# STM32F407 register map
File version: 1.4
CPU: CM4 r0p1, little endian, MPU, FPU, 4 interrupt priority bits
Registers are 32-bit, read-write, reset 0x0 unless marked. A register's access mark holds for its fields unless they carry their own. Offsets are from the block's base; [hi:lo] are bit positions; {n}, {i} and the like mark numbered series.

## GPIOA — General-purpose I/Os
Base 0x40020000
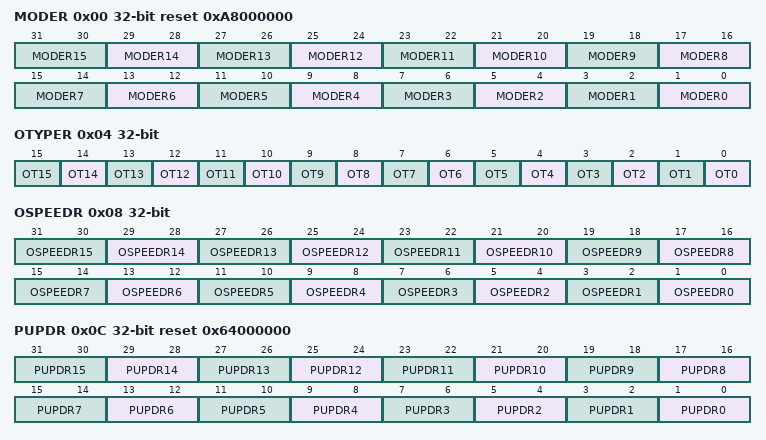
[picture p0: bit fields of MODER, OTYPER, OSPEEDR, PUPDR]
0x00 MODER reset 0xA8000000 — GPIO port mode register
  [2n+1:2n] MODER{n} (n=0..15) — Port x configuration bits (y = 0..15)
0x04 OTYPER — GPIO port output type register
  [n] OT{n} (n=0..15) — Port x configuration bits (y = 0..15)
0x08 OSPEEDR — GPIO port output speed register
  [2n+1:2n] OSPEEDR{n} (n=0..15) — Port x configuration bits (y = 0..15)
0x0C PUPDR reset 0x64000000 — GPIO port pull-up/pull-down register
  [2n+1:2n] PUPDR{n} (n=0..15) — Port x configuration bits (y = 0..15)
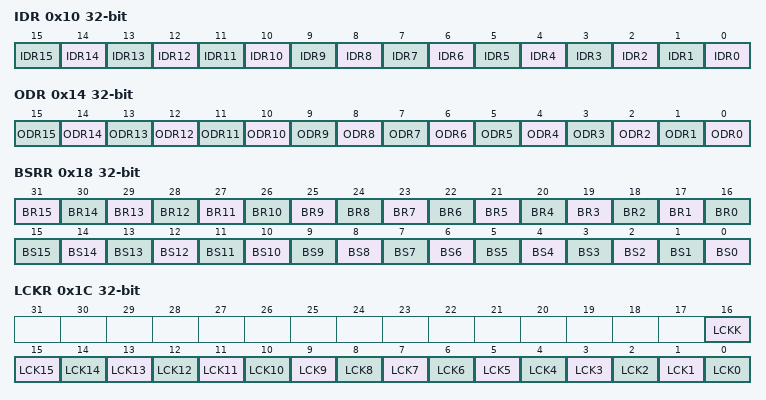
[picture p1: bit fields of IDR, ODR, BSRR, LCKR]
0x10 IDR ro — GPIO port input data register
  [n] IDR{n} (n=0..15) — Port input data (y = 0..15)
0x14 ODR — GPIO port output data register
  [n] ODR{n} (n=0..15) — Port output data (y = 0..15)
0x18 BSRR wo — GPIO port bit set/reset register
  [n+16] BR{n} (n=1..15) — Port x reset bit y (y = 0..15)
  [16] BR0 — Port x set bit y (y= 0..15)
  [n] BS{n} (n=0..15) — Port x set bit y (y= 0..15)
0x1C LCKR — GPIO port configuration lock register
  [16] LCKK — Port x lock bit y (y= 0..15)
  [n] LCK{n} (n=0..15) — Port x lock bit y (y= 0..15)
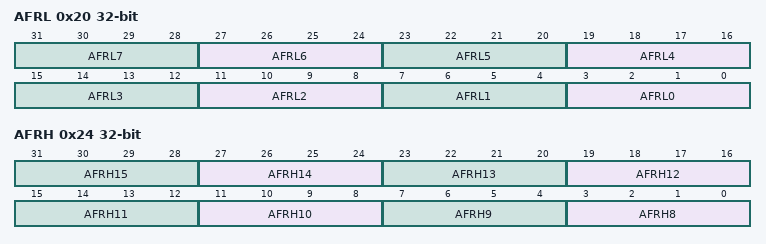
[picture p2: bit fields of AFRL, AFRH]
0x20 AFRL — GPIO alternate function low register
  [4n+3:4n] AFRL{n} (n=0..7) — Alternate function selection for port x bit y (y = 0..7)
0x24 AFRH — GPIO alternate function high register
  [4n-29:4n-32] AFRH{n} (n=8..15) — Alternate function selection for port x bit y (y = 8..15)

## GPIOB — General-purpose I/Os
Base 0x40020400
Registers as GPIOA; these are added or differ:
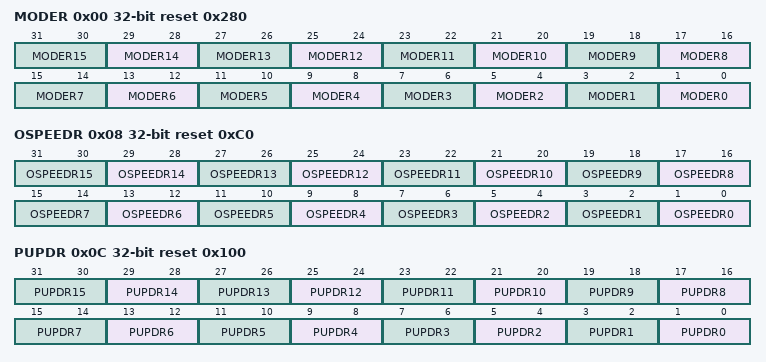
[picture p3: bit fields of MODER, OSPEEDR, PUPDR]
0x00 MODER reset 0x280 — GPIO port mode register
  [2n+1:2n] MODER{n} (n=0..15) — Port x configuration bits (y = 0..15)
0x08 OSPEEDR reset 0xC0 — GPIO port output speed register
  [2n+1:2n] OSPEEDR{n} (n=0..15) — Port x configuration bits (y = 0..15)
0x0C PUPDR reset 0x100 — GPIO port pull-up/pull-down register
  [2n+1:2n] PUPDR{n} (n=0..15) — Port x configuration bits (y = 0..15)

## GPIOC — General-purpose I/Os
Base 0x40020800
Same registers: GPIOD 0x40020C00, GPIOE 0x40021000, GPIOF 0x40021400, GPIOG 0x40021800, GPIOH 0x40021C00, GPIOI 0x40022000, GPIOJ 0x40022400, GPIOK 0x40022800
Registers as GPIOA; these are added or differ:
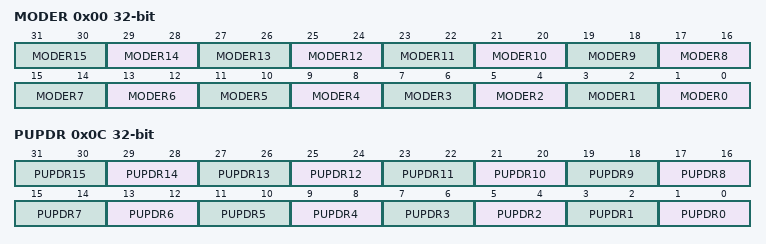
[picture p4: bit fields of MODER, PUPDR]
0x00 MODER — GPIO port mode register
  [2n+1:2n] MODER{n} (n=0..15) — Port x configuration bits (y = 0..15)
0x0C PUPDR — GPIO port pull-up/pull-down register
  [2n+1:2n] PUPDR{n} (n=0..15) — Port x configuration bits (y = 0..15)

## TIM6 — Basic timers
Base 0x40001000
Same registers: TIM7 0x40001400
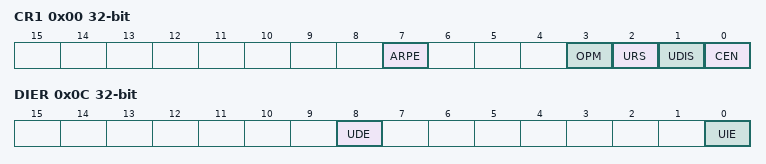
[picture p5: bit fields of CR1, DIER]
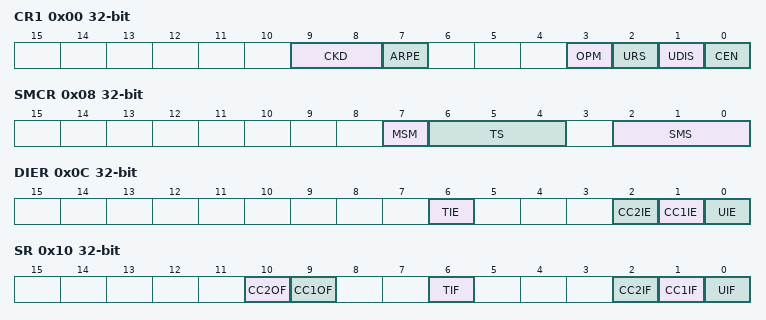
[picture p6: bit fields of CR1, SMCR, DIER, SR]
0x00 CR1 — control register 1
  [7] ARPE — Auto-reload preload enable
  [3] OPM — One-pulse mode
  [2] URS — Update request source
  [1] UDIS — Update disable
  [0] CEN — Counter enable
0x04 CR2 — control register 2
  [6:4] MMS — Master mode selection
0x0C DIER — DMA/Interrupt enable register
  [8] UDE — Update DMA request enable
  [0] UIE — Update interrupt enable
0x10 SR — status register
  [0] UIF — Update interrupt flag
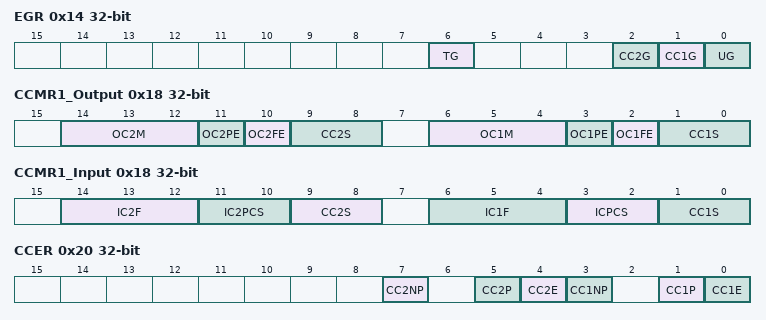
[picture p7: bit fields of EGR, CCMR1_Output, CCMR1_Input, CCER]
0x14 EGR wo — event generation register
  [0] UG — Update generation
0x24 CNT — counter
  [15:0] CNT — Low counter value
0x28 PSC — prescaler
  [15:0] PSC — Prescaler value
0x2C ARR — auto-reload register
  [15:0] ARR — Low Auto-reload value

## TIM9 — General purpose timers
Base 0x40014000
Same registers: TIM12 0x40001800
0x00 CR1 — control register 1
  [9:8] CKD — Clock division
  [7] ARPE — Auto-reload preload enable
  [3] OPM — One-pulse mode
  [2] URS — Update request source
  [1] UDIS — Update disable
  [0] CEN — Counter enable
0x04 CR2 — control register 2
  [6:4] MMS — Master mode selection
0x08 SMCR — slave mode control register
  [7] MSM — Master/Slave mode
  [6:4] TS — Trigger selection
  [2:0] SMS — Slave mode selection
0x0C DIER — DMA/Interrupt enable register
  [6] TIE — Trigger interrupt enable
  [2] CC2IE — Capture/Compare 2 interrupt enable
  [1] CC1IE — Capture/Compare 1 interrupt enable
  [0] UIE — Update interrupt enable
0x10 SR — status register
  [10] CC2OF — Capture/compare 2 overcapture flag
  [9] CC1OF — Capture/Compare 1 overcapture flag
  [6] TIF — Trigger interrupt flag
  [2] CC2IF — Capture/Compare 2 interrupt flag
  [1] CC1IF — Capture/compare 1 interrupt flag
  [0] UIF — Update interrupt flag
0x14 EGR wo — event generation register
  [6] TG — Trigger generation
  [2] CC2G — Capture/compare 2 generation
  [1] CC1G — Capture/compare 1 generation
  [0] UG — Update generation
0x18 CCMR1_Output — capture/compare mode register 1 (output mode)
  [14:12] OC2M — Output Compare 2 mode
  [11] OC2PE — Output Compare 2 preload enable
  [10] OC2FE — Output Compare 2 fast enable
  [9:8] CC2S — Capture/Compare 2 selection
  [6:4] OC1M — Output Compare 1 mode
  [3] OC1PE — Output Compare 1 preload enable
  [2] OC1FE — Output Compare 1 fast enable
  [1:0] CC1S — Capture/Compare 1 selection
0x18 CCMR1_Input (alternate view of CCMR1_Output) — capture/compare mode register 1 (input mode)
  [14:12] IC2F — Input capture 2 filter
  [11:10] IC2PCS — Input capture 2 prescaler
  [9:8] CC2S — Capture/Compare 2 selection
  [6:4] IC1F — Input capture 1 filter
  [3:2] ICPCS — Input capture 1 prescaler
  [1:0] CC1S — Capture/Compare 1 selection
0x20 CCER — capture/compare enable register
  [7] CC2NP — Capture/Compare 2 output Polarity
  [5] CC2P — Capture/Compare 2 output Polarity
  [4] CC2E — Capture/Compare 2 output enable
  [3] CC1NP — Capture/Compare 1 output Polarity
  [1] CC1P — Capture/Compare 1 output Polarity
  [0] CC1E — Capture/Compare 1 output enable
0x24 CNT — counter
  [15:0] CNT — counter value
0x28 PSC — prescaler
  [15:0] PSC — Prescaler value
0x2C ARR — auto-reload register
  [15:0] ARR — Auto-reload value
0x34 CCR1 — capture/compare register 1
  [15:0] CCR1 — Capture/Compare 1 value
0x38 CCR2 — capture/compare register 2
  [15:0] CCR2 — Capture/Compare 2 value
